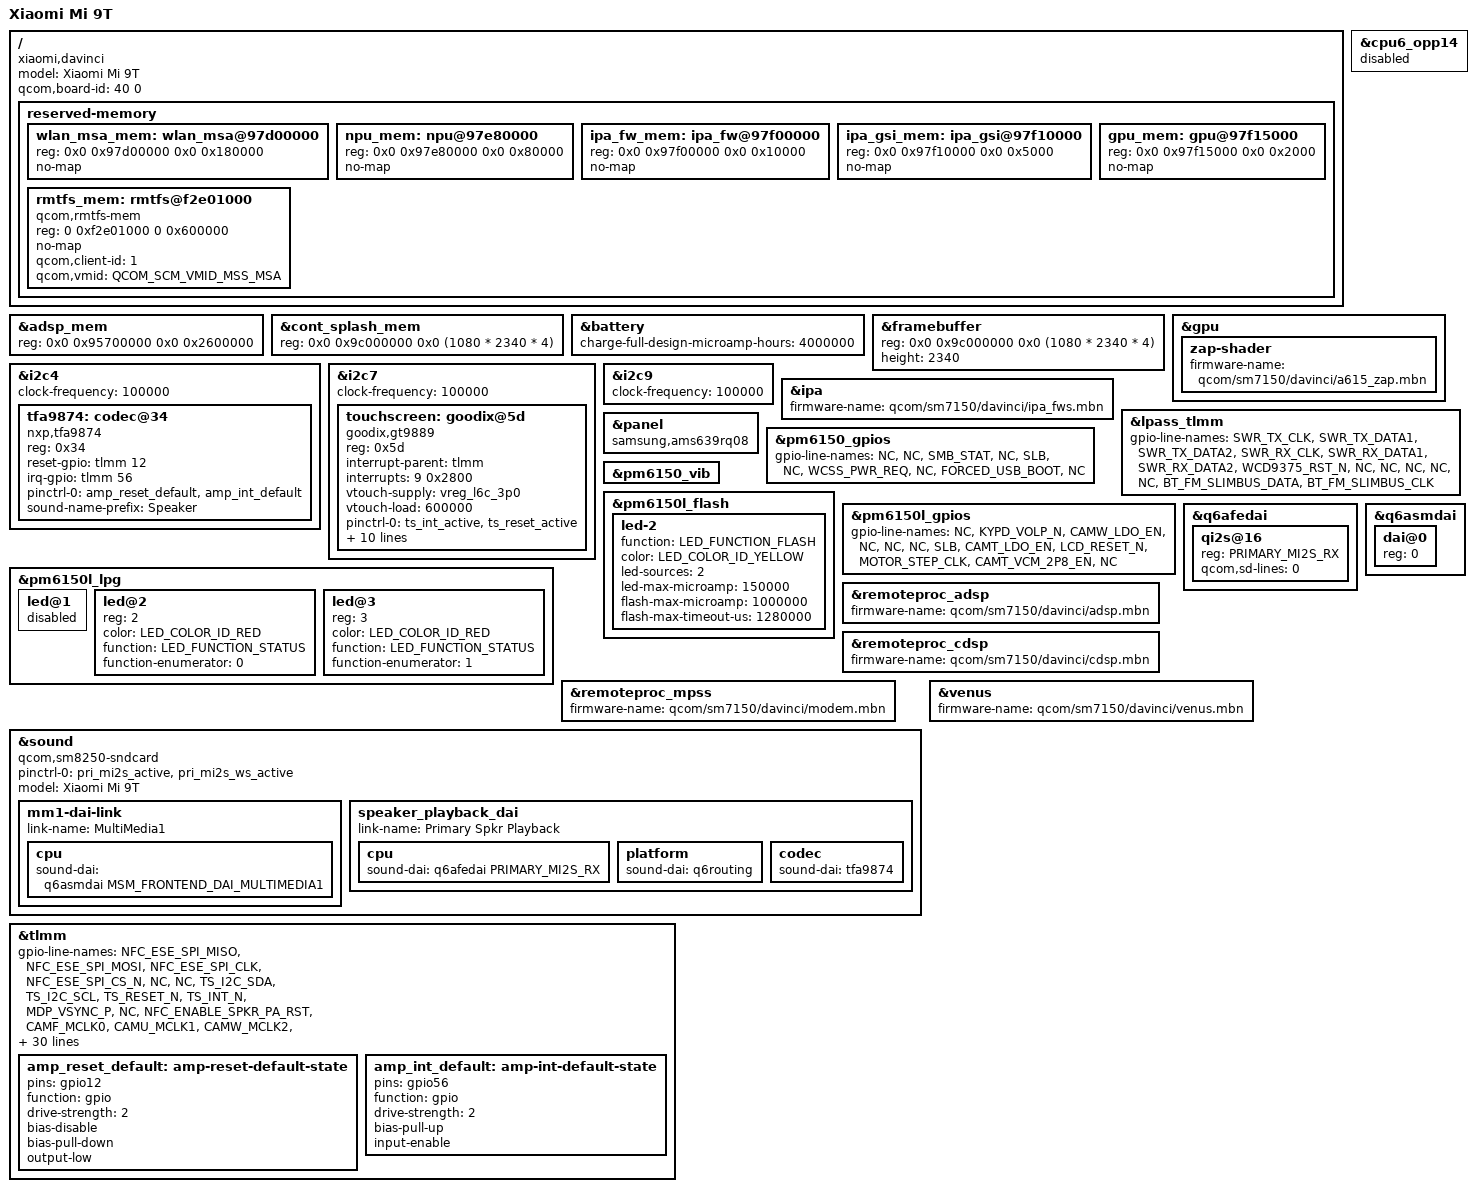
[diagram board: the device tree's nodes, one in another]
// SPDX-License-Identifier: BSD-3-Clause
/*
 * SM7150-AA Xiaomi Mi 9T / Redmi K20 specific device tree
 *
 * Copyright (c) 2024, Danila Tikhonov <danila@jiaxyga.com>
 * Copyright (c) 2024, Jens Reidel <adrian@travitia.xyz>
 */

/dts-v1/;

#include "sm7150-xiaomi-common.dtsi"

/delete-node/ &wlan_msa_mem;
/delete-node/ &npu_mem;
/delete-node/ &ipa_fw_mem;
/delete-node/ &ipa_gsi_mem;
/delete-node/ &gpu_mem;
/* The NFC reset-gpio is shared with the pinctrl of the amplifier. Disable NFC so that audio works. */
/delete-node/ &nxp;

&adsp_mem {
	reg = <0x0 0x95700000 0x0 0x2600000>;
};

&cont_splash_mem {
	reg = <0x0 0x9c000000 0x0 (1080 * 2340 * 4)>;
};

/*
 * Davinci uses the SM7150-AA SoC.
 * Limit CPU clock to 2.2 GHz
 */

&cpu6_opp14 {
	status = "disabled";
};

/ {
	/*
	 * Xiaomi Mi 9T
	 * Xiaomi Redmi K20
	 */
	model = "Xiaomi Mi 9T";
	compatible = "xiaomi,davinci", "qcom,sm7150";

	qcom,board-id = <40 0>;

	reserved-memory {
		wlan_msa_mem: wlan_msa@97d00000 {
			reg = <0x0 0x97d00000 0x0 0x180000>;
			no-map;
		};

		npu_mem: npu@97e80000 {
			reg = <0x0 0x97e80000 0x0 0x80000>;
			no-map;
		};

		ipa_fw_mem: ipa_fw@97f00000 {
			reg = <0x0 0x97f00000 0x0 0x10000>;
			no-map;
		};

		ipa_gsi_mem: ipa_gsi@97f10000 {
			reg = <0x0 0x97f10000 0x0 0x5000>;
			no-map;
		};

		gpu_mem: gpu@97f15000 {
			reg = <0x0 0x97f15000 0x0 0x2000>;
			no-map;
		};

		rmtfs_mem: rmtfs@f2e01000 {
			compatible = "qcom,rmtfs-mem";
			reg = <0 0xf2e01000 0 0x600000>;
			no-map;

			qcom,client-id = <1>;
			qcom,vmid = <QCOM_SCM_VMID_MSS_MSA>;
		};
	};
};

&battery {
	charge-full-design-microamp-hours = <4000000>;
};

&framebuffer {
	reg = <0x0 0x9c000000 0x0 (1080 * 2340 * 4)>;
	height = <2340>;
};

&gpu {
	zap-shader {
		firmware-name = "qcom/sm7150/davinci/a615_zap.mbn";
	};
};

&i2c4 {
	clock-frequency = <100000>;
	status = "okay";

	tfa9874: codec@34 {
		compatible = "nxp,tfa9874";
		reg = <0x34>;

		reset-gpio = <&tlmm 12 GPIO_ACTIVE_HIGH>;
		irq-gpio = <&tlmm 56 GPIO_ACTIVE_HIGH>;

		pinctrl-names = "default";
		pinctrl-0 = <&amp_reset_default &amp_int_default>;

		sound-name-prefix = "Speaker";
		#sound-dai-cells = <0>;
	};
};

&i2c7 {
	clock-frequency = <100000>;
	status = "okay";

	touchscreen: goodix@5d {
		compatible = "goodix,gt9889";
		reg = <0x5d>;
		interrupt-parent = <&tlmm>;
		interrupts = <9 0x2800>;
		vtouch-supply = <&vreg_l6c_3p0>; /* 3v3 */
		vtouch-load = <600000>;
		pinctrl-0 = <&ts_int_active &ts_reset_active>;
		pinctrl-1 = <&ts_int_suspend &ts_reset_suspend>;
		pinctrl-names = "default", "sleep";
		goodix,reset-gpio = <&tlmm 8 GPIO_ACTIVE_HIGH>;
		goodix,irq-gpio = <&tlmm 9 0x2800>;
		goodix,avdd-name = "vtouch";
		goodix,irq-flags = <2>; /* trigger falling;*/
		goodix,panel-max-x = <1079>;
		goodix,panel-max-y = <2339>;
		goodix,panel-max-w = <127>;
		goodix,power-on-delay-us = <300000>; /* 300ms */
		goodix,power-off-delay-us = <5000>; /* 50ms */
	};
};

&i2c9 {
	clock-frequency = <100000>;
	status = "okay";

	/* asahi-kasei,akm09970 (magnetometer) @ 0c */
	/* qcom,smb1390 (charger) @ 10 */
};

&ipa {
	firmware-name = "qcom/sm7150/davinci/ipa_fws.mbn";
};

&lpass_tlmm {
	gpio-line-names = "SWR_TX_CLK", /* GPIO_0 */
			  "SWR_TX_DATA1",
			  "SWR_TX_DATA2",
			  "SWR_RX_CLK",
			  "SWR_RX_DATA1",
			  "SWR_RX_DATA2",
			  "WCD9375_RST_N",
			  "NC",
			  "NC",
			  "NC",
			  "NC", /* GPIO_10 */
			  "NC",
			  "BT_FM_SLIMBUS_DATA",
			  "BT_FM_SLIMBUS_CLK";
};

&panel {
	compatible = "samsung,ams639rq08"; // or visionox,g1639fp106
};

&pm6150_gpios {
	gpio-line-names = "NC", /* GPIO_1 */
			  "NC",
			  "SMB_STAT",
			  "NC",
			  "SLB",
			  "NC",
			  "WCSS_PWR_REQ",
			  "NC",
			  "FORCED_USB_BOOT",
			  "NC";  /* GPIO_10 */
};

&pm6150_vib {
	status = "okay";
};

&pm6150l_flash {
	status = "okay";

	led-2 {
		function = LED_FUNCTION_FLASH;
		color = <LED_COLOR_ID_YELLOW>;
		led-sources = <2>;
		led-max-microamp = <150000>;
		flash-max-microamp = <1000000>;
		flash-max-timeout-us = <1280000>;
	};
};

&pm6150l_gpios {
	gpio-line-names = "NC", /* GPIO_1 */
			  "KYPD_VOLP_N",
			  "CAMW_LDO_EN",
			  "NC",
			  "NC",
			  "NC",
			  "SLB",
			  "CAMT_LDO_EN",
			  "LCD_RESET_N",
			  "MOTOR_STEP_CLK", /* GPIO_10 */
			  "CAMT_VCM_2P8_EN",
			  "NC";
};

&pm6150l_lpg {
	status = "okay";

	led@1 {
		status = "disabled";
	};

	led@2 {
		reg = <2>;
		color = <LED_COLOR_ID_RED>;
		function = LED_FUNCTION_STATUS;
		function-enumerator = <0>;
	};

	led@3 {
		reg = <3>;
		color = <LED_COLOR_ID_RED>;
		function = LED_FUNCTION_STATUS;
		function-enumerator = <1>;
	};
};

&q6afedai {
	qi2s@16 {
		reg = <PRIMARY_MI2S_RX>;
		qcom,sd-lines = <0>;
	};
};

&q6asmdai {
	dai@0 {
		reg = <0>;
	};
};

&remoteproc_adsp {
	firmware-name = "qcom/sm7150/davinci/adsp.mbn";
};

&remoteproc_cdsp {
	firmware-name = "qcom/sm7150/davinci/cdsp.mbn";
};

&remoteproc_mpss {
	firmware-name = "qcom/sm7150/davinci/modem.mbn";
};

&sound {
	compatible = "qcom,sm8250-sndcard";
	pinctrl-0 = <&pri_mi2s_active &pri_mi2s_ws_active>;
	pinctrl-names = "default";
	model = "Xiaomi Mi 9T";

	mm1-dai-link {
		link-name = "MultiMedia1";
		cpu {
			sound-dai = <&q6asmdai MSM_FRONTEND_DAI_MULTIMEDIA1>;
		};
	};

	speaker_playback_dai {
		link-name = "Primary Spkr Playback";
		cpu {
			sound-dai = <&q6afedai PRIMARY_MI2S_RX>;
		};

		platform {
			sound-dai = <&q6routing>;
		};

		codec {
			sound-dai = <&tfa9874>;
		};
	};
};

&tlmm {
	gpio-line-names = "NFC_ESE_SPI_MISO", /* GPIO_0 */
			  "NFC_ESE_SPI_MOSI",
			  "NFC_ESE_SPI_CLK",
			  "NFC_ESE_SPI_CS_N",
			  "NC",
			  "NC",
			  "TS_I2C_SDA",
			  "TS_I2C_SCL",
			  "TS_RESET_N",
			  "TS_INT_N",
			  "MDP_VSYNC_P", /* GPIO_10 */
			  "NC",
			  "NFC_ENABLE_SPKR_PA_RST",
			  "CAMF_MCLK0",
			  "CAMU_MCLK1",
			  "CAMW_MCLK2",
			  "CAMT_MCLK3",
			  "CCI_I2C_SDA0",
			  "CCI_I2C_SCL0",
			  "CCI_I2C_SDA1",
			  "CCI_I2C_SCL1", /* GPIO_20 */
			  "NC",
			  "FL_STROBE_TRIG",
			  "CAMF_RSTN",
			  "CAMT_RSTN",
			  "CAMU_RSTN",
			  "CAMW_RSTN",
			  "CCI_I2C_SDA2",
			  "CCI_I2C_SCL2",
			  "CAMU_LDO_EN",
			  "NC",  /* GPIO_30 */
			  "NFC_LABBCLK3_EN",
			  "ERR_INT_N",
			  "AUDIO_SWITCH_EN",
			  "NFC_I2C_SDA",
			  "NFC_I2C_SCL",
			  "NFC_DWL_REQ",
			  "NFC_IRQ",
			  "BT_UART_CTS",
			  "BT_UART_RFR",
			  "BT_UART_TX", /* GPIO_40 */
			  "BT_UART_RX",
			  "LCD_ID_DET1",
			  "MOTOR_FAULT",
			  "BLSP2_UART_TX",
			  "BLSP2_UART_RX",
			  "APPS_I2C_SDA",
			  "APPS_I2C_SCL",
			  "FORCED_USB_BOOT",
			  "SPKR_I2S_BCK",
			  "SPKR_I2S_WS", /* GPIO_50 */
			  "SPKR_I2S_DOUT",
			  "SPKR_I2S_DIN1",
			  "SPKR_I2C_SDA",
			  "SPKR_I2C_SCL",
			  "MOTOR_DIR",
			  "SPKR_INT",
			  "CAMF_LDO_EN",
			  "NC",
			  "FOD_SPI_MISO",
			  "FOD_SPI_MOSI", /* GPIO_60 */
			  "FOD_SPI_SCLK",
			  "FOD_SPI_CS_N",
			  "FOD_LDO_EN",
			  "DIGITAL_HALL1_RSTN",
			  "FOD_RST",
			  "MOTOR_M1",
			  "SPKR_PA_RST_NFC_ENABLE",
			  "TS_TA",
			  "FOD_INT",
			  "RFFE6_CLK", /* GPIO_70 */
			  "RFFE6_DATA",
			  "FM_GPIO",
			  "WLAN_SW_CTRL",
			  "GRFC_4",
			  "UIM2_DATA",
			  "UIM2_CLK",
			  "UIM2_RESET",
			  "UIM2_PRESENT",
			  "UIM1_DATA",
			  "UIM1_CLK", /* GPIO_80 */
			  "UIM1_RESET",
			  "UIM1_PRESENT",
			  "GRFC_8",
			  "GRFC_9",
			  "WMSS_RESET_N",
			  "ACCEL_INT",
			  "GYRO_INT",
			  "MOTOR_SLEEP",
			  "ALS_INT_N",
			  "MOTOR_EN", /* GPIO_90 */
			  "MOTOR_M0",
			  "RFFE4_CLK",
			  "DIGITAL_HALL1_INT",
			  "NC",
			  "GRFC_3",
			  "QLINK_REQUEST",
			  "QLINK_ENABLE",
			  "GRFC_2",
			  "NC",
			  "GRFC_1", /* GPIO_100 */
			  "RFFE3_DATA",
			  "RFFE3_CLK",
			  "RFFE4_DATA",
			  "USB_PHY_PS",
			  "RFFE5_DATA",
			  "RFFE5_CLK",
			  "NC",
			  "WLAN_COEX_UART_TXD",
			  "WLAN_COEX_UART_RXD",
			  "NC", /* GPIO_110 */
			  "NC",
			  "RFFE1_DATA",
			  "RFFE1_CLK";

	amp_reset_default: amp-reset-default-state {
		pins = "gpio12";
		function = "gpio";
		drive-strength = <2>;
		bias-disable;
		bias-pull-down;
		output-low;
	};

	amp_int_default: amp-int-default-state {
		pins = "gpio56";
		function = "gpio";
		drive-strength = <2>;
		bias-pull-up;
		input-enable;
	};
};

&venus {
	firmware-name = "qcom/sm7150/davinci/venus.mbn";
};
